VERSION ""

NS_ :

BS_:

BU_: AUTO_GEARBOX_SWITCH CMB FMUX IDB PASS_VSM VSM DSGN_DIAG FMUX_DIAG

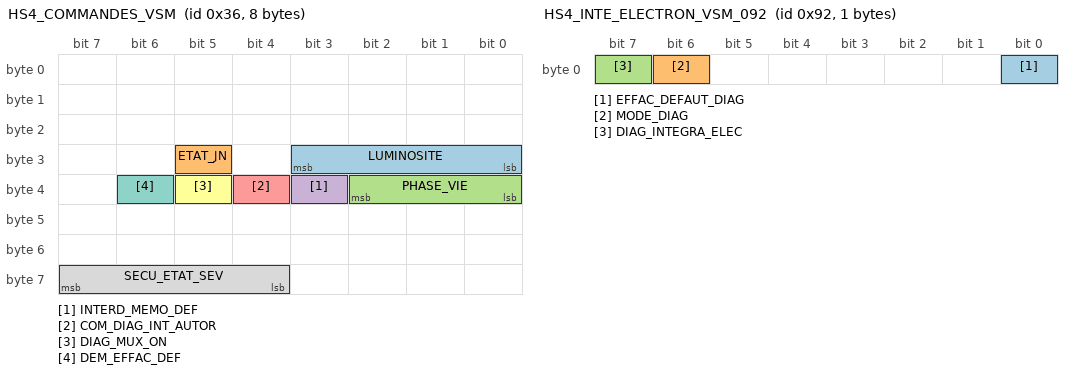
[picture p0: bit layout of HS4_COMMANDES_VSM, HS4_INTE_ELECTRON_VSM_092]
BO_ 54 HS4_COMMANDES_VSM: 8 VSM
 SG_ LUMINOSITE : 27|4@0+ (1,0) [0|15] "" AUTO_GEARBOX_SWITCH,CMB,FMUX,IDB
 SG_ ETAT_JN : 29|1@0+ (1,0) [0|0] "" AUTO_GEARBOX_SWITCH,CMB,FMUX,IDB
 SG_ PHASE_VIE : 34|3@0+ (1,0) [0|0] "" AUTO_GEARBOX_SWITCH,CMB,FMUX,IDB
 SG_ INTERD_MEMO_DEF : 35|1@0+ (1,0) [0|0] "" AUTO_GEARBOX_SWITCH,CMB,FMUX,IDB
 SG_ COM_DIAG_INT_AUTOR : 36|1@0+ (1,0) [0|0] "" AUTO_GEARBOX_SWITCH,CMB,FMUX,IDB
 SG_ DIAG_MUX_ON : 37|1@0+ (1,0) [0|0] "" AUTO_GEARBOX_SWITCH,CMB,FMUX,IDB
 SG_ DEM_EFFAC_DEF : 38|1@0+ (1,0) [0|0] "" AUTO_GEARBOX_SWITCH,CMB,FMUX,IDB
 SG_ SECU_ETAT_SEV : 63|4@0+ (1,0) [0|0] "" AUTO_GEARBOX_SWITCH,CMB,FMUX,IDB

BO_ 146 HS4_INTE_ELECTRON_VSM_092: 1 VSM
 SG_ EFFAC_DEFAUT_DIAG : 0|1@0+ (1,0) [0|0] "" AUTO_GEARBOX_SWITCH,CMB,FMUX,IDB
 SG_ MODE_DIAG : 6|1@0+ (1,0) [0|0] "" AUTO_GEARBOX_SWITCH,CMB,FMUX,IDB
 SG_ DIAG_INTEGRA_ELEC : 7|1@0+ (1,0) [0|0] "" AUTO_GEARBOX_SWITCH,CMB,FMUX,IDB

BO_ 182 HS4_DONNEES_VSM_RAPIDES: 8 VSM
 SG_ VITV : 23|16@0+ (0.01,0) [0|655.34] "km/h" AUTO_GEARBOX_SWITCH,CMB,FMUX,IDB

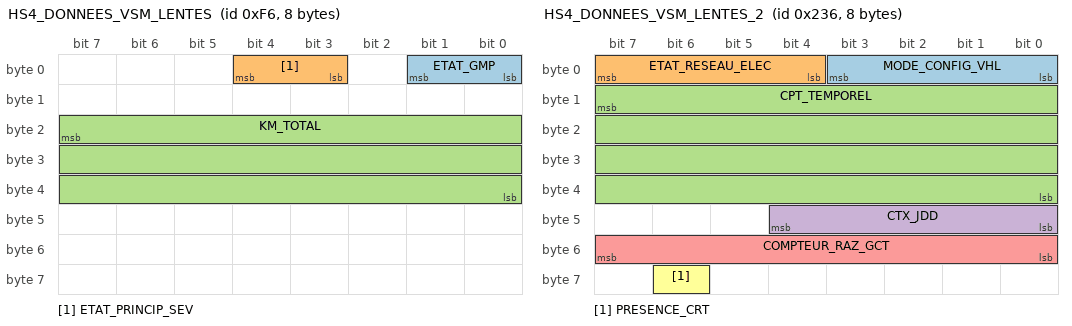
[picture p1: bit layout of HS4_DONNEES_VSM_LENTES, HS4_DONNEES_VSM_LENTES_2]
BO_ 246 HS4_DONNEES_VSM_LENTES: 8 VSM
 SG_ ETAT_GMP : 1|2@0+ (1,0) [0|0] "" AUTO_GEARBOX_SWITCH,CMB,FMUX,IDB
 SG_ ETAT_PRINCIP_SEV : 4|2@0+ (1,0) [0|0] "" AUTO_GEARBOX_SWITCH,CMB,FMUX,IDB
 SG_ KM_TOTAL : 23|24@0+ (0.1,0) [0|1677721.4] "km" AUTO_GEARBOX_SWITCH,CMB,FMUX,IDB

BO_ 290 HS4_ETAT_FMUX: 8 CMB
 SG_ PUSH_8 : 0|1@0+ (1,0) [0|0] "" PASS_VSM
 SG_ PUSH_7 : 1|1@0+ (1,0) [0|0] "" PASS_VSM
 SG_ PUSH_6 : 2|1@0+ (1,0) [0|0] "" PASS_VSM
 SG_ PUSH_5 : 3|1@0+ (1,0) [0|0] "" PASS_VSM
 SG_ PUSH_4 : 4|1@0+ (1,0) [0|0] "" PASS_VSM
 SG_ PUSH_3 : 5|1@0+ (1,0) [0|0] "" PASS_VSM
 SG_ PUSH_2 : 6|1@0+ (1,0) [0|0] "" PASS_VSM
 SG_ PUSH_1 : 7|1@0+ (1,0) [0|0] "" PASS_VSM
 SG_ PUSH_16 : 8|1@0+ (1,0) [0|0] "" PASS_VSM
 SG_ PUSH_15 : 9|1@0+ (1,0) [0|0] "" PASS_VSM
 SG_ PUSH_14 : 10|1@0+ (1,0) [0|0] "" PASS_VSM
 SG_ PUSH_13 : 11|1@0+ (1,0) [0|0] "" PASS_VSM
 SG_ PUSH_12 : 12|1@0+ (1,0) [0|0] "" PASS_VSM
 SG_ PUSH_11 : 13|1@0+ (1,0) [0|0] "" PASS_VSM
 SG_ PUSH_10 : 14|1@0+ (1,0) [0|0] "" PASS_VSM
 SG_ PUSH_9 : 15|1@0+ (1,0) [0|0] "" PASS_VSM
 SG_ PUSH_24 : 16|1@0+ (1,0) [0|0] "" PASS_VSM
 SG_ PUSH_23 : 17|1@0+ (1,0) [0|0] "" PASS_VSM
 SG_ PUSH_22 : 18|1@0+ (1,0) [0|0] "" PASS_VSM
 SG_ PUSH_21 : 19|1@0+ (1,0) [0|0] "" PASS_VSM
 SG_ PUSH_20 : 20|1@0+ (1,0) [0|0] "" PASS_VSM
 SG_ PUSH_19 : 21|1@0+ (1,0) [0|0] "" PASS_VSM
 SG_ PUSH_18 : 22|1@0+ (1,0) [0|0] "" PASS_VSM
 SG_ PUSH_17 : 23|1@0+ (1,0) [0|0] "" PASS_VSM
 SG_ PUSH_32 : 24|1@0+ (1,0) [0|0] "" PASS_VSM
 SG_ PUSH_31 : 25|1@0+ (1,0) [0|0] "" PASS_VSM
 SG_ PUSH_30 : 26|1@0+ (1,0) [0|0] "" PASS_VSM
 SG_ PUSH_29 : 27|1@0+ (1,0) [0|0] "" PASS_VSM
 SG_ PUSH_28 : 28|1@0+ (1,0) [0|0] "" PASS_VSM
 SG_ PUSH_27 : 29|1@0+ (1,0) [0|0] "" PASS_VSM
 SG_ PUSH_26 : 30|1@0+ (1,0) [0|0] "" PASS_VSM
 SG_ PUSH_25 : 31|1@0+ (1,0) [0|0] "" PASS_VSM
 SG_ PUSH_40 : 32|1@0+ (1,0) [0|0] "" PASS_VSM
 SG_ PUSH_39 : 33|1@0+ (1,0) [0|0] "" PASS_VSM
 SG_ PUSH_38 : 34|1@0+ (1,0) [0|0] "" PASS_VSM
 SG_ PUSH_37 : 35|1@0+ (1,0) [0|0] "" PASS_VSM
 SG_ PUSH_36 : 36|1@0+ (1,0) [0|0] "" PASS_VSM
 SG_ PUSH_35 : 37|1@0+ (1,0) [0|0] "" PASS_VSM
 SG_ PUSH_34 : 38|1@0+ (1,0) [0|0] "" PASS_VSM
 SG_ PUSH_33 : 39|1@0+ (1,0) [0|0] "" PASS_VSM
 SG_ SYNC_MOL_FAC_2 : 40|1@0+ (1,0) [0|0] "" PASS_VSM
 SG_ SYNC_MOL_FAC_1 : 41|1@0+ (1,0) [0|0] "" PASS_VSM
 SG_ PUSH_44 : 44|1@0+ (1,0) [0|0] "" PASS_VSM
 SG_ PUSH_43 : 45|1@0+ (1,0) [0|0] "" PASS_VSM
 SG_ PUSH_42 : 46|1@0+ (1,0) [0|0] "" PASS_VSM
 SG_ PUSH_41 : 47|1@0+ (1,0) [0|0] "" PASS_VSM
 SG_ CPT_MOL_FAC_1 : 55|8@0+ (1,0) [0|255] "" PASS_VSM
 SG_ CPT_MOL_FAC_2 : 63|8@0+ (1,0) [0|255] "" PASS_VSM

BO_ 544 HS4_VSM_INF_PROFILS_2: 8 VSM
 SG_ UNITE_TEMPERATURE : 16|1@0+ (1,0) [0|0] "" CMB,FMUX
 SG_ DISPO_UNITES_LANGUE : 19|1@0+ (1,0) [0|0] "" CMB,FMUX

BO_ 551 HS4_CDE_LED_PUSH: 8 VSM
 SG_ SORTIE_PUSH_FREIN_SEC_ELE : 15|2@0+ (1,0) [0|0] "" CMB,FMUX
 SG_ P_LED_HADC_PUSH : 35|1@0+ (1,0) [0|0] "" CMB,FMUX

BO_ 566 HS4_DONNEES_VSM_LENTES_2: 8 VSM
 SG_ MODE_CONFIG_VHL : 3|4@0+ (1,0) [0|0] "" AUTO_GEARBOX_SWITCH,CMB,FMUX,IDB
 SG_ ETAT_RESEAU_ELEC : 7|4@0+ (1,0) [0|0] "" AUTO_GEARBOX_SWITCH,CMB,FMUX,IDB
 SG_ CPT_TEMPOREL : 15|32@0+ (0.1,0) [0|429496729.3] "s" AUTO_GEARBOX_SWITCH,CMB,FMUX,IDB
 SG_ CTX_JDD : 44|5@0+ (0,0) [0|0] "" AUTO_GEARBOX_SWITCH,CMB,FMUX,IDB
 SG_ COMPTEUR_RAZ_GCT : 55|8@0+ (1,0) [0|253] "" AUTO_GEARBOX_SWITCH,CMB,FMUX,IDB
 SG_ PRESENCE_CRT : 62|1@0+ (1,0) [0|0] "" AUTO_GEARBOX_SWITCH,CMB,FMUX,IDB

BO_ 630 HS4_DONNEES_VSM_LENTES_3: 8 VSM
 SG_ ANNEE_HORLOGE : 6|7@0+ (1,2000) [0|125] "Year" AUTO_GEARBOX_SWITCH,CMB,FMUX,IDB
 SG_ MODE_HEURE_CLIENT : 7|1@0+ (1,0) [0|0] "" AUTO_GEARBOX_SWITCH,CMB,FMUX,IDB
 SG_ MOIS_HORLOGE : 11|4@0+ (1,0) [0|0] "" AUTO_GEARBOX_SWITCH,CMB,FMUX,IDB
 SG_ AFFICHAGE_HORLOGE : 12|1@0+ (1,0) [0|0] "" AUTO_GEARBOX_SWITCH,CMB,FMUX,IDB
 SG_ ETAT_CONDA : 15|3@0+ (1,0) [0|0] "" AUTO_GEARBOX_SWITCH,CMB,FMUX,IDB
 SG_ JOUR_HORLOGE : 21|6@0+ (1,0) [1|31] "day" AUTO_GEARBOX_SWITCH,CMB,FMUX,IDB
 SG_ EE_ARCHITECTURE : 22|1@0+ (1,0) [0|0] "" AUTO_GEARBOX_SWITCH,CMB,FMUX,IDB
 SG_ HEURE_HORLOGE : 28|5@0+ (1,0) [0|23] "hour" AUTO_GEARBOX_SWITCH,CMB,FMUX,IDB
 SG_ MINUTE_HORLOGE : 37|6@0+ (1,0) [0|59] "min" AUTO_GEARBOX_SWITCH,CMB,FMUX,IDB
 SG_ DEEP_SLEEP_MODE : 39|2@0+ (1,0) [0|0] "" AUTO_GEARBOX_SWITCH,CMB,FMUX,IDB
 SG_ AUTONOMIE_UREE : 45|14@0+ (1,0) [0|10000] "km" AUTO_GEARBOX_SWITCH,CMB,FMUX,IDB
 SG_ DMD_AFF_AUTON_UREE : 47|1@0+ (1,0) [0|0] "" AUTO_GEARBOX_SWITCH,CMB,FMUX,IDB
 SG_ POS_SHUNT_JDD : 57|2@0+ (1,0) [0|0] "" AUTO_GEARBOX_SWITCH,CMB,FMUX,IDB
 SG_ ETAT_SELECTIVITE_OUV_AR : 58|1@0+ (1,0) [0|0] "" AUTO_GEARBOX_SWITCH,CMB,FMUX,IDB
 SG_ ETAT_SELECTIVITE_COND : 59|1@0+ (1,0) [0|0] "" AUTO_GEARBOX_SWITCH,CMB,FMUX,IDB
 SG_ ETAT_SELECTIVITE_CAB_ZC : 60|1@0+ (1,0) [0|0] "" AUTO_GEARBOX_SWITCH,CMB,FMUX,IDB
 SG_ ETAT_SELECTIVITE : 61|1@0+ (1,0) [0|0] "" AUTO_GEARBOX_SWITCH,CMB,FMUX,IDB
 SG_ ETAT_CONDA_OUV_AR : 62|1@0+ (1,0) [0|0] "" AUTO_GEARBOX_SWITCH,CMB,FMUX,IDB
 SG_ ETAT_CONDA_COFFRE : 63|1@0+ (1,0) [0|0] "" AUTO_GEARBOX_SWITCH,CMB,FMUX,IDB

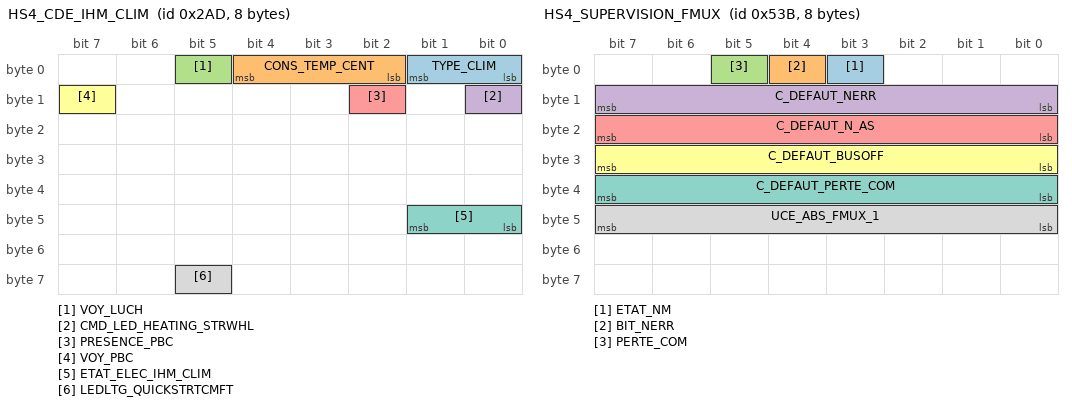
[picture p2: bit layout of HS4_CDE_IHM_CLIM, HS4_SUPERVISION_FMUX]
BO_ 685 HS4_CDE_IHM_CLIM: 8 VSM
 SG_ TYPE_CLIM : 1|2@0+ (1,0) [0|0] "" CMB,FMUX
 SG_ CONS_TEMP_CENT : 4|3@0+ (1,0) [0|0] "" CMB,FMUX
 SG_ VOY_LUCH : 5|1@0+ (1,0) [0|0] "" CMB,FMUX
 SG_ CMD_LED_HEATING_STRWHL : 8|1@0+ (1,0) [0|0] "" CMB,FMUX
 SG_ PRESENCE_PBC : 10|1@0+ (1,0) [0|0] "" CMB,FMUX
 SG_ VOY_PBC : 15|1@0+ (1,0) [0|0] "" CMB,FMUX
 SG_ ETAT_ELEC_IHM_CLIM : 41|2@0+ (1,0) [0|0] "" CMB,FMUX
 SG_ LEDLTG_QUICKSTRTCMFT : 61|1@0+ (1,0) [0|0] "" CMB,FMUX

BO_ 749 HS4_CDE_IHM_CLIM_2: 7 VSM
 SG_ DISTRIBUTION_AVG : 3|4@0+ (1,0) [0|0] "" FMUX
 SG_ DISTRIBUTION_AVD : 7|4@0+ (1,0) [0|0] "" FMUX
 SG_ DMD_SIEGE_CHAUF_AVD : 9|2@0+ (1,0) [0|0] "" FMUX
 SG_ DMD_AC : 11|2@0+ (1,0) [0|0] "" FMUX
 SG_ PULS_AV : 15|4@0+ (1,0) [0|0] "" FMUX
 SG_ ETAT_MONO : 16|1@0+ (1,0) [0|0] "" FMUX
 SG_ ETAT_AC_MAX : 17|1@0+ (1,0) [0|0] "" FMUX
 SG_ DMD_SIEGE_VENTIL_AVG : 19|2@0+ (1,0) [0|0] "" FMUX
 SG_ DMD_SIEGE_VENTIL_AVD : 21|2@0+ (1,0) [0|0] "" FMUX
 SG_ DMD_SIEGE_CHAUF_AVG : 23|2@0+ (1,0) [0|0] "" FMUX
 SG_ ENTREE_AIR : 26|3@0+ (1,0) [0|0] "" FMUX
 SG_ VAL_CONS_TEMP_AVD : 31|5@0+ (1,0) [0|0] "" FMUX
 SG_ DMD_VISI : 32|1@0+ (1,0) [0|0] "" FMUX
 SG_ TYPAGE : 34|2@0+ (1,0) [0|0] "" FMUX
 SG_ VAL_CONS_TEMP_AVG : 39|5@0+ (1,0) [0|0] "" FMUX
 SG_ DMD_PUSH_3NIV_S_CHAUF_ARD : 40|2@0+ (1,0) [0|0] "" FMUX
 SG_ ETAT_AUTO_AVC : 41|1@0+ (1,0) [0|0] "" FMUX
 SG_ ETAT_PULSEUR : 45|4@0+ (1,0) [0|0] "" FMUX
 SG_ ETAT_REAR : 47|2@0+ (1,0) [0|0] "" FMUX
 SG_ DMD_PUSH_3NIV_VENTIL_S_ARG : 50|2@0+ (1,0) [0|0] "" FMUX
 SG_ DMD_PUSH_3NIV_VENTIL_S_ARD : 52|2@0+ (1,0) [0|0] "" FMUX
 SG_ DMD_PUSH_3NIV_S_CHAUF_ARG : 54|2@0+ (1,0) [0|0] "" FMUX

BO_ 867 HS4_INFO_IHM_3: 8 VSM
 SG_ DMD_REAR_LOCKED : 56|1@0+ (1,0) [0|0] "" CMB,FMUX

BO_ 869 HS4_ETAT_PUSH_PHYS: 8 FMUX
 SG_ DMDP_3LVL_FAN_SEAT_FR : 0|1@0+ (1,0) [0|0] "" VSM
 SG_ DMDP_3LVL_FAN_SEAT_FL : 1|1@0+ (1,0) [0|0] "" VSM
 SG_ DMDP_3LVL_HEAT_SEAT_FR : 2|1@0+ (1,0) [0|0] "" VSM
 SG_ DMDP_3LVL_HEAT_SEAT_FL : 3|1@0+ (1,0) [0|0] "" VSM
 SG_ DEFAUT_MOLETTE_TEMP_AVG : 4|1@0+ (1,0) [0|0] "" VSM
 SG_ DMDP_AC_MAX_PHYS : 5|1@0+ (1,0) [0|0] "" VSM
 SG_ DEFAUT_MOLETTE_TEMP_AVD : 6|1@0+ (1,0) [0|0] "" VSM
 SG_ DEFAUT_MOLETTE_PULS_AV : 7|1@0+ (1,0) [0|0] "" VSM
 SG_ DMDP_DIST_AVD_PIED_PHYS : 8|1@0+ (1,0) [0|0] "" VSM
 SG_ DMDP_DIST_AVD_DEGI_PHYS : 9|1@0+ (1,0) [0|0] "" VSM
 SG_ DMDP_DIST_AVD_AERATION_PHYS : 10|1@0+ (1,0) [0|0] "" VSM
 SG_ DMDP_CHGT_NIVEAU_SLIDER_PHYS : 11|1@0+ (1,0) [0|0] "" VSM
 SG_ DMDP_CHGT_DEGIVRAGE_PHYS : 12|1@0+ (1,0) [0|0] "" VSM
 SG_ DMDP_AUTO_NORMAL_PHYS : 13|1@0+ (1,0) [0|0] "" VSM
 SG_ DMDP_AUTO_LEGER_PHYS : 14|1@0+ (1,0) [0|0] "" VSM
 SG_ DMDP_AUTO_FORT_PHYS : 15|1@0+ (1,0) [0|0] "" VSM
 SG_ DMDP_PULSEUR_AV_PLUS_PHYS : 16|1@0+ (1,0) [0|0] "" VSM
 SG_ DMDP_PULSEUR_AV_MOINS_PHYS : 17|1@0+ (1,0) [0|0] "" VSM
 SG_ DMDP_OFF_AV_PHYS : 18|1@0+ (1,0) [0|0] "" VSM
 SG_ DMDP_MONO_PHYS : 19|1@0+ (1,0) [0|0] "" VSM
 SG_ DMDP_ENTREE_AIR_PHYS : 20|1@0+ (1,0) [0|0] "" VSM
 SG_ DMDP_DIST_AVG_PIED_PHYS : 21|1@0+ (1,0) [0|0] "" VSM
 SG_ DMDP_DIST_AVG_DEGI_PHYS : 22|1@0+ (1,0) [0|0] "" VSM
 SG_ DMDP_DIST_AVG_AERATION_PHYS : 23|1@0+ (1,0) [0|0] "" VSM
 SG_ DMDP_TEMP_AVD_PLUS_PHYS : 24|1@0+ (1,0) [0|0] "" VSM
 SG_ DMDP_TEMP_AVD_MOINS_PHYS : 25|1@0+ (1,0) [0|0] "" VSM
 SG_ DMDP_NIVEAU_TEMP_AVD_PHYS : 31|5@0+ (1,0) [0|0] "" VSM
 SG_ DMDP_VISIBILITE_PHYS : 32|1@0+ (1,0) [0|0] "" VSM
 SG_ DMDP_TEMP_AVG_PLUS_PHYS : 33|1@0+ (1,0) [0|0] "" VSM
 SG_ DMDP_TEMP_AVG_MOINS_PHYS : 34|1@0+ (1,0) [0|0] "" VSM
 SG_ DMDP_NIVEAU_TEMP_AVG_PHYS : 39|5@0+ (1,0) [0|0] "" VSM
 SG_ BTNPSD_QUICKSTRTCMFT : 40|1@0+ (1,0) [0|0] "" VSM
 SG_ ENT_PUSH_SAM : 41|1@0+ (1,0) [0|0] "" VSM
 SG_ DMDP_AUTO_PHYS : 42|1@0+ (1,0) [0|0] "" VSM
 SG_ DMDP_CHGT_CHAUF_PARE_BRISE : 43|1@0+ (1,0) [0|0] "" VSM
 SG_ DMDP_NIVEAU_PULSEUR_AV_PHYS : 47|4@0+ (1,0) [0|0] "" VSM
 SG_ DMD_TEMP_PLUS : 48|1@0+ (1,0) [0|0] "" VSM
 SG_ DMD_TEMP_MOINS : 49|1@0+ (1,0) [0|0] "" VSM
 SG_ DMD_AUTO : 50|1@0+ (1,0) [0|0] "" VSM
 SG_ DMD_PULSEUR_MOINS : 51|1@0+ (1,0) [0|0] "" VSM
 SG_ DMD_PULSEUR_PLUS : 52|1@0+ (1,0) [0|0] "" VSM
 SG_ HW_LED_HADC_PUSH : 53|1@0+ (1,0) [0|0] "" VSM
 SG_ REQ_HEATING_STRWHL : 54|1@0+ (1,0) [0|0] "" Vector__XXX
 SG_ DMDP_AC_PHYS : 55|1@0+ (1,0) [0|0] "" VSM
 SG_ HADC_PUSH_STATE : 56|1@0+ (1,0) [0|0] "" VSM
 SG_ DMDP_NIVEAU_PULSEUR_ARG : 59|3@0+ (1,0) [0|0] "" VSM
 SG_ DMDP_3LVL_FAN_SEAT_RR : 60|1@0+ (1,0) [0|0] "" VSM
 SG_ DMDP_3LVL_FAN_SEAT_RL : 61|1@0+ (1,0) [0|0] "" VSM
 SG_ DMDP_3LVL_HEAT_SEAT_RL : 62|1@0+ (1,0) [0|0] "" VSM
 SG_ DMDP_3LVL_HEAT_SEAT_RR : 63|1@0+ (1,0) [0|0] "" VSM

BO_ 1142 HS4_ACK_EVT_DEF: 1 VSM
 SG_ REP_UCE : 7|8@0+ (0,0) [0|0] "" AUTO_GEARBOX_SWITCH,CMB,FMUX,IDB

BO_ 1211 HS4_FLT_EVT_FMUX: 8 FMUX
 SG_ TYPE_MESSAGE : 1|2@0+ (1,0) [0|0] "" Vector__XXX
 SG_ RELEVANCE_OF_DATE : 2|1@0+ (1,0) [0|0] "" Vector__XXX
 SG_ ETAT_DTC : 3|1@0+ (1,0) [0|0] "" Vector__XXX
 SG_ NUMERO_TRAME : 5|2@0+ (1,0) [0|0] "" Vector__XXX
 SG_ NOMBRE_TRAMES : 7|2@0+ (1,0) [0|0] "" Vector__XXX
 SG_ CODES_DEFAUT : 15|24@0+ (0,0) [0|0] "" Vector__XXX
 SG_ KILOMETRAGE_DEH : 15|24@0+ (0.1,0) [0|1677721.4] "km" Vector__XXX
 SG_ DTCFORMATIDENTIFIER : 39|8@0+ (1,0) [0|0] "" Vector__XXX
 SG_ REFERENCE_HORAIRE : 39|32@0+ (0.1,0) [0|429496729.3] "s" Vector__XXX
 SG_ ECU_CODE : 47|8@0+ (0,0) [0|0] "No Unit" Vector__XXX

BO_ 1339 HS4_SUPERVISION_FMUX: 8 FMUX
 SG_ ETAT_NM : 3|1@0+ (1,0) [0|0] "" Vector__XXX
 SG_ BIT_NERR : 4|1@0+ (1,0) [0|0] "" Vector__XXX
 SG_ PERTE_COM : 5|1@0+ (1,0) [0|0] "" Vector__XXX
 SG_ C_DEFAUT_NERR : 15|8@0+ (1,0) [0|255] "" Vector__XXX
 SG_ C_DEFAUT_N_AS : 23|8@0+ (1,0) [0|255] "" Vector__XXX
 SG_ C_DEFAUT_BUSOFF : 31|8@0+ (1,0) [0|255] "" Vector__XXX
 SG_ C_DEFAUT_PERTE_COM : 39|8@0+ (1,0) [0|255] "" Vector__XXX
 SG_ UCE_ABS_FMUX_1 : 47|8@0+ (1,0) [0|0] "" Vector__XXX

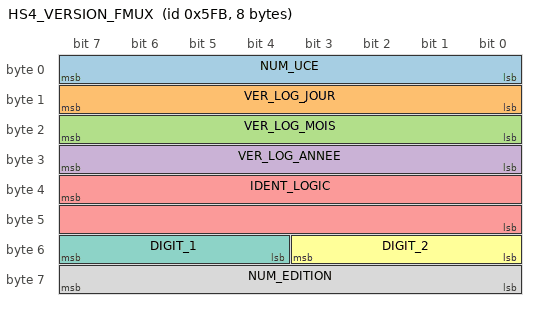
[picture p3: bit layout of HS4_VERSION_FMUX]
BO_ 1531 HS4_VERSION_FMUX: 8 FMUX
 SG_ NUM_UCE : 7|8@0+ (1,0) [0|254] "" Vector__XXX
 SG_ VER_LOG_JOUR : 15|8@0+ (1,0) [1|31] "day" Vector__XXX
 SG_ VER_LOG_MOIS : 23|8@0+ (1,0) [1|12] "month" Vector__XXX
 SG_ VER_LOG_ANNEE : 31|8@0+ (1,2000) [2000|2200] "" Vector__XXX
 SG_ IDENT_LOGIC : 39|16@0+ (1,0) [0|65534] "" Vector__XXX
 SG_ DIGIT_2 : 51|4@0+ (1,0) [0|0] "" Vector__XXX
 SG_ DIGIT_1 : 55|4@0+ (1,0) [0|15] "" Vector__XXX
 SG_ NUM_EDITION : 63|8@0+ (1,0) [0|254] "" Vector__XXX

BO_ 1659 HS4_REP_DIAG_FMUX: 8 FMUX
 SG_ DATA_DIAG : 7|64@0+ (0,0) [0|0] "" PASS_VSM

BO_ 1814 HS4_REP_DIAG_LIN_FMUX: 8 FMUX
 SG_ DATA_DIAG : 7|64@0+ (0,0) [0|0] "" PASS_VSM

BO_ 1846 HS4_REQ_DIAG_LIN_FMUX: 8 PASS_VSM
 SG_ DATA_DIAG : 7|64@0+ (0,0) [0|0] "" FMUX

BO_ 1915 HS4_REQ_DIAG_FMUX: 8 PASS_VSM
 SG_ DATA_DIAG : 7|64@0+ (0,0) [0|0] "" FMUX
